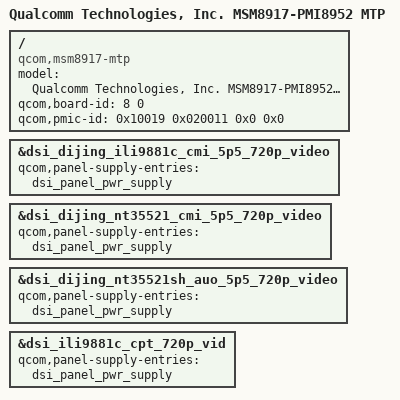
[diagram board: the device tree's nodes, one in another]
/*
 * Copyright (c) 2017, The Linux Foundation. All rights reserved.
 *
 * This program is free software; you can redistribute it and/or modify
 * it under the terms of the GNU General Public License version 2 and
 * only version 2 as published by the Free Software Foundation.
 *
 * This program is distributed in the hope that it will be useful,
 * but WITHOUT ANY WARRANTY; without even the implied warranty of
 * MERCHANTABILITY or FITNESS FOR A PARTICULAR PURPOSE.  See the
 * GNU General Public License for more details.
 */

/dts-v1/;

#include "../msm8917.dtsi"
#include "../msm8917-audio.dtsi"
#include "../msm8917-mtp.dtsi"
#include "../msm8917-pmi8950.dtsi"
#include "../msm8917-pmi8950-mtp.dtsi"
#include "zte-msm8917-pmi8950-peony.dtsi"
#include "qualcomm_base_diff.dtsi"

#include "dsi-panel-zte-dijing-nt35521-cmi-5p5-720p-video.dtsi"
#include "dsi-panel-zte-lead-ili9881c-cpt-5p5-720p-video.dtsi"
#include "dsi-panel-zte-tianma-s6d7aa6-tm-5p5-720p-video.dtsi"
#include "dsi-panel-zte-dijing-nt35521sh-auo-5p5-720p-video.dtsi"
#include "dsi-panel-zte-dijing-ili9881c-cmi-5p5-720p-video.dtsi"


/ {
	model = "Qualcomm Technologies, Inc. MSM8917-PMI8952 MTP";
	compatible = "qcom,msm8917-mtp", "qcom,msm8917", "qcom,mtp";
	qcom,board-id = <8 0>;
	qcom,pmic-id = <0x10019 0x020011 0x0 0x0>;
};

&dsi_dijing_ili9881c_cmi_5p5_720p_video {
		qcom,panel-supply-entries = <&dsi_panel_pwr_supply>;
};
&dsi_dijing_nt35521_cmi_5p5_720p_video {
		qcom,panel-supply-entries = <&dsi_panel_pwr_supply>;
};
&dsi_dijing_nt35521sh_auo_5p5_720p_video {
		qcom,panel-supply-entries = <&dsi_panel_pwr_supply>;
};
&dsi_ili9881c_cpt_720p_vid {
		qcom,panel-supply-entries = <&dsi_panel_pwr_supply>;
};
